# ATSAMA5D31 register map
Vendor: Microchip Technology; Series: SAMA5D3; File version: 0
Registers are 32-bit, read-write, reset 0x0 unless marked. A register's access mark holds for its fields unless they carry their own. Offsets are from the block's base; [hi:lo] are bit positions; lines under a group give offsets from that group; {n}, {i} and the like mark numbered series; 'fields as' and 'values as' point back to an identical list.

## DMAC0 — DMA Controller
Base 0xFFFFE600; register names take the prefix DMAC_
Same registers: DMAC1 0xFFFFE800
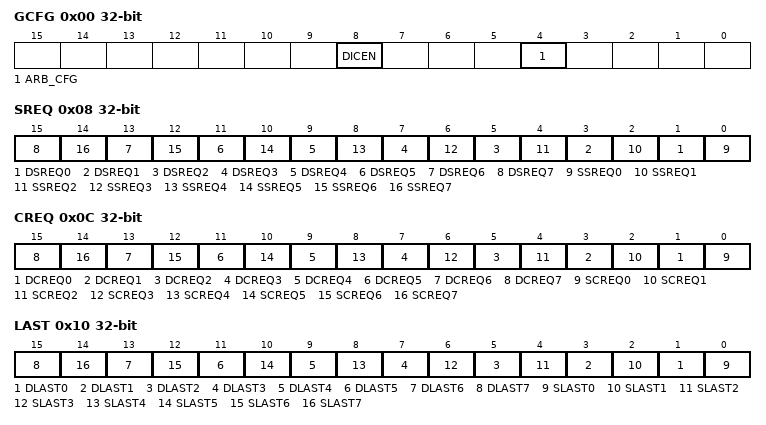
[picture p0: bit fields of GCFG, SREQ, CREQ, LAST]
0x00 GCFG — DMAC Global Configuration Register
  [8] DICEN — Descriptor Integrity Check
  [4] ARB_CFG — Arbiter Configuration
    0=FIXED (Fixed priority arbiter (see 'Basic Definitions' )); 1=ROUND_ROBIN (Modified round robin arbiter.)
0x04 EN — DMAC Enable Register
  [0] ENABLE — General Enable of DMA
0x08 SREQ — DMAC Software Single Request Register
  [2n+1] DSREQ{n} (n=0..7) — Destination Request
  [2n] SSREQ{n} (n=0..7) — Source Request
0x0C CREQ — DMAC Software Chunk Transfer Request Register
  [2n+1] DCREQ{n} (n=0..7) — Destination Chunk Request
  [2n] SCREQ{n} (n=0..7) — Source Chunk Request
0x10 LAST — DMAC Software Last Transfer Flag Register
  [2n+1] DLAST{n} (n=0..7) — Destination Last
  [2n] SLAST{n} (n=0..7) — Source Last
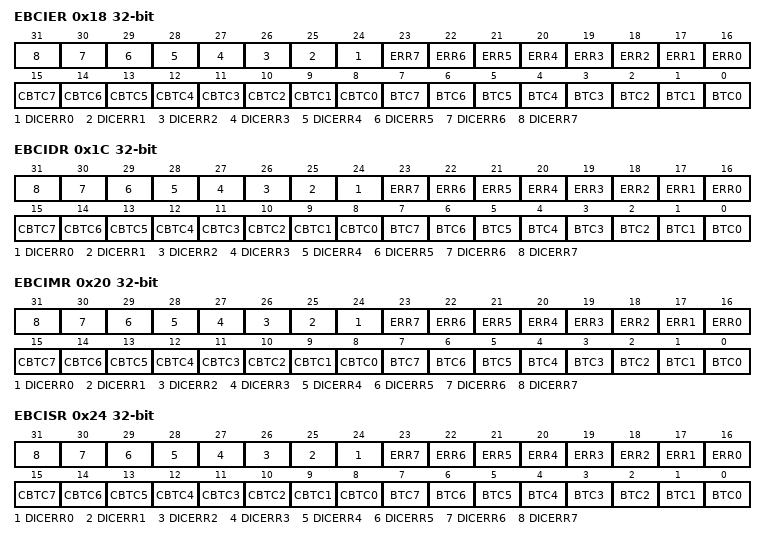
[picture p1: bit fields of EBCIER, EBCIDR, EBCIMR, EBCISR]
0x18 EBCIER wo — DMAC Error, Chained Buffer Transfer Completed Interrupt and Buffer Transfer Completed Interrupt Enable Register
  [n+24] DICERR{n} (n=0..7) — Descriptor Integrity Check Error [7:0]
  [n+16] ERR{n} (n=0..7) — Access Error [7:0]
  [n+8] CBTC{n} (n=0..7) — Chained Buffer Transfer Completed [7:0]
  [n] BTC{n} (n=0..7) — Buffer Transfer Completed [7:0]
0x1C EBCIDR wo — DMAC Error, Chained Buffer Transfer Completed Interrupt and Buffer Transfer Completed Interrupt Disable Register
  fields as EBCIER
0x20 EBCIMR ro — DMAC Error, Chained Buffer Transfer Completed Interrupt and Buffer transfer completed Mask Register
  fields as EBCIER
0x24 EBCISR ro — DMAC Error, Chained Buffer Transfer Completed Interrupt and Buffer transfer completed Status Register
  fields as EBCIER
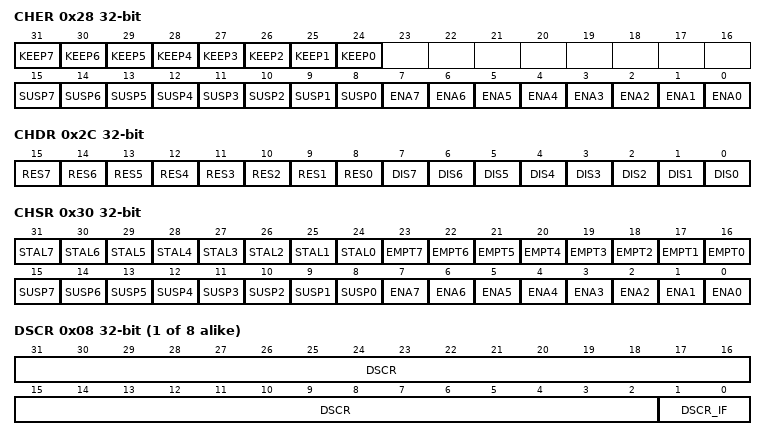
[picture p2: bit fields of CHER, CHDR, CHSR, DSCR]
0x28 CHER wo — DMAC Channel Handler Enable Register
  [n+24] KEEP{n} (n=0..7) — Keep on [7:0]
  [n+8] SUSP{n} (n=0..7) — Suspend [7:0]
  [n] ENA{n} (n=0..7) — Enable [7:0]
0x2C CHDR wo — DMAC Channel Handler Disable Register
  [n+8] RES{n} (n=0..7) — Resume [7:0]
  [n] DIS{n} (n=0..7) — Disable [7:0]
0x30 CHSR ro — DMAC Channel Handler Status Register
  [n+24] STAL{n} (n=0..7) — Stalled [7:0]
  [n+16] EMPT{n} (n=0..7) — Empty [7:0]
  [n+8] SUSP{n} (n=0..7) — Suspend [7:0]
  [n] ENA{n} (n=0..7) — Enable [7:0]
{0x3C+0x28*i} DMAC_CH_NUM[{i}] (i=0..7) group
  0x00 SADDR — DMAC Channel Source Address Register
    [31:0] SADDR — Channel x Source Address
  0x04 DADDR — DMAC Channel Destination Address Register
    [31:0] DADDR — Channel x Destination Address
  0x08 DSCR — DMAC Channel Descriptor Address Register
    [31:2] DSCR — Buffer Transfer Descriptor Address
    [1:0] DSCR_IF — Descriptor Interface Selection
      0=AHB_IF0 (The buffer transfer descriptor is fetched via AHB-Lite Interface 0 (first DMA Master Interface)); 1=AHB_IF1 (The buffer transfer descriptor is fetched via AHB-Lite Interface 1 (second DMA Master Interface)); 2=AHB_IF2 (The buffer transfer descriptor is fetched via AHB-Lite Interface 2 (third DMA Master Interface))
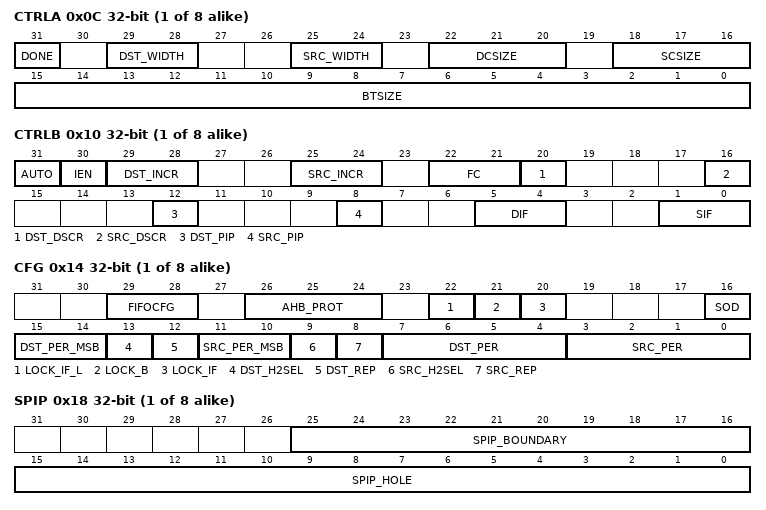
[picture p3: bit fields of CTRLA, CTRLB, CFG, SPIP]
  0x0C CTRLA — DMAC Channel Control A Register
    [31] DONE — Current Descriptor Stop Command and Transfer Completed Memory Indicator
    [29:28] DST_WIDTH — Transfer Width for the Destination
      0=BYTE (The transfer size is set to 8-bit width); 1=HALF_WORD (The transfer size is set to 16-bit width); 2=WORD (The transfer size is set to 32-bit width); 3=DWORD (The transfer size is set to 64-bit width)
    [25:24] SRC_WIDTH — Transfer Width for the Source
      values as DST_WIDTH
    [22:20] DCSIZE — Destination Chunk Transfer Size
      0=CHK_1 (1 data transferred); 1=CHK_4 (4 data transferred); 2=CHK_8 (8 data transferred); 3=CHK_16 (16 data transferred)
    [18:16] SCSIZE — Source Chunk Transfer Size
      values as DCSIZE
    [15:0] BTSIZE — Buffer Transfer Size
  0x10 CTRLB — DMAC Channel Control B Register
    [31] AUTO — Automatic Multiple Buffer Transfer
      0=DISABLE (Automatic multiple buffer transfer is disabled.); 1=ENABLE (Automatic multiple buffer transfer is enabled. This bit enables replay mode or contiguous mode when several buffers are transferred.)
    [30] IEN — Interrupt Enable Not
    [29:28] DST_INCR — Incrementing, Decrementing or Fixed Address for the Destination
      0=INCREMENTING (The destination address is incremented); 1=DECREMENTING (The destination address is decremented); 2=FIXED (The destination address remains unchanged)
    [25:24] SRC_INCR — Incrementing, Decrementing or Fixed Address for the Source
      0=INCREMENTING (The source address is incremented); 1=DECREMENTING (The source address is decremented); 2=FIXED (The source address remains unchanged)
    [22:21] FC — Flow Control
      0=MEM2MEM_DMA_FC (Memory-to-Memory Transfer DMAC is flow controller); 1=MEM2PER_DMA_FC (Memory-to-Peripheral Transfer DMAC is flow controller); 2=PER2MEM_DMA_FC (Peripheral-to-Memory Transfer DMAC is flow controller); 3=PER2PER_DMA_FC (Peripheral-to-Peripheral Transfer DMAC is flow controller)
    [20] DST_DSCR — Destination Address Descriptor
      0=FETCH_FROM_MEM (Destination address is updated when the descriptor is fetched from the memory.); 1=FETCH_DISABLE (Buffer Descriptor Fetch operation is disabled for the destination.)
    [16] SRC_DSCR — Source Address Descriptor
      0=FETCH_FROM_MEM (Source address is updated when the descriptor is fetched from the memory.); 1=FETCH_DISABLE (Buffer Descriptor Fetch operation is disabled for the source.)
    [12] DST_PIP — Destination Picture-in-Picture Mode
      0=DISABLE (Picture-in-Picture mode is disabled. The Destination data area is contiguous.); 1=ENABLE (Picture-in-Picture mode is enabled. When the Destination PIP counter reaches the programmable boundary the address is automatically incremented by a user-defined amount.)
    [8] SRC_PIP — Source Picture-in-Picture Mode
      0=DISABLE (Picture-in-Picture mode is disabled. The source data area is contiguous.); 1=ENABLE (Picture-in-Picture mode is enabled. When the source PIP counter reaches the programmable boundary, the address is automatically incremented by a user defined amount.)
    [5:4] DIF — Destination Interface Selection Field
      0=AHB_IF0 (The destination transfer is done via AHB_Lite Interface 0 (first DMA Master Interface)); 1=AHB_IF1 (The destination transfer is done via AHB_Lite Interface 1 (second DMA Master Interface)); 2=AHB_IF2 (The destination transfer is done via AHB_Lite Interface 2 (third DMA Master Interface))
    [1:0] SIF — Source Interface Selection Field
      0=AHB_IF0 (The source transfer is done via AHB_Lite Interface 0 (first DMA Master Interface)); 1=AHB_IF1 (The source transfer is done via AHB_Lite Interface 1 (second DMA Master Interface)); 2=AHB_IF2 (The source transfer is done via AHB_Lite Interface 2 (third DMA Master Interface))
  0x14 CFG — DMAC Channel Configuration Register
    [29:28] FIFOCFG — FIFO Configuration
      0=ALAP_CFG (The largest defined length AHB burst is performed on the destination AHB interface.); 1=HALF_CFG (When half FIFO size is available/filled, a source/destination request is serviced.); 2=ASAP_CFG (When there is enough space/data available to perform a single AHB access, then the request is serviced.)
    [26:24] AHB_PROT — AHB Protection
    [22] LOCK_IF_L — Master Interface Arbiter Lock
      0=CHUNK (The Master Interface Arbiter is locked by the channel x for a chunk transfer.); 1=BUFFER (The Master Interface Arbiter is locked by the channel x for a buffer transfer.)
    [21] LOCK_B — Bus Lock
      0=DISABLE (AHB Bus Locking capability is disabled.)
    [20] LOCK_IF — Interface Lock
      0=DISABLE (Interface Lock capability is disabled); 1=ENABLE (Interface Lock capability is enabled)
    [16] SOD — Stop On Done
      0=DISABLE (STOP ON DONE disabled, the descriptor fetch operation ignores the DMAC_CTRLAx.DONE bit.); 1=ENABLE (STOP ON DONE activated, the DMAC module is automatically disabled if DMAC_CTRLAx.DONE bit is set.)
    [15:14] DST_PER_MSB — DST_PER Most Significant Bits
    [13] DST_H2SEL — Software or Hardware Selection for the Destination
      0=SW (Software handshaking interface is used to trigger a transfer request.); 1=HW (Hardware handshaking interface is used to trigger a transfer request.)
    [12] DST_REP — Destination Reloaded from Previous
      0=CONTIGUOUS_ADDR (When automatic mode is activated, destination address is contiguous between two buffers.); 1=RELOAD_ADDR (When automatic mode is activated, the destination and the control register are reloaded from the pre-vious transfer.)
    [11:10] SRC_PER_MSB — SRC_PER Most Significant Bits
    [9] SRC_H2SEL — Software or Hardware Selection for the Source
      values as DST_H2SEL
    [8] SRC_REP — Source Reloaded from Previous
      0=CONTIGUOUS_ADDR (When automatic mode is activated, source address is contiguous between two buffers.); 1=RELOAD_ADDR (When automatic mode is activated, the source address and the control register are reloaded from previous transfer.)
    [7:4] DST_PER — Destination with Peripheral identifier
    [3:0] SRC_PER — Source with Peripheral identifier
  0x18 SPIP — DMAC Channel Source Picture-in-Picture Configuration Register
    [25:16] SPIP_BOUNDARY — Source Picture-in-Picture Boundary
    [15:0] SPIP_HOLE — Source Picture-in-Picture Hole
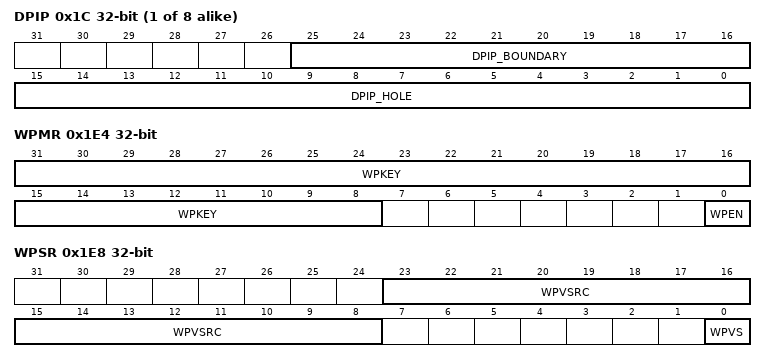
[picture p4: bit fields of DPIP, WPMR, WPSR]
  0x1C DPIP — DMAC Channel Destination Picture-in-Picture Configuration Register
    [25:16] DPIP_BOUNDARY — Destination Picture-in-Picture Boundary
    [15:0] DPIP_HOLE — Destination Picture-in-Picture Hole
0x1E4 WPMR — DMAC Write Protection Mode Register
  [31:8] WPKEY — Write Protection Key
    0x444D41=PASSWD (Writing any other value in this field aborts the write operation of the WPEN bit.Always reads as 0.)
  [0] WPEN — Write Protection Enable
0x1E8 WPSR ro — DMAC Write Protection Status Register
  [23:8] WPVSRC — Write Protection Violation Source
  [0] WPVS — Write Protection Violation Status
